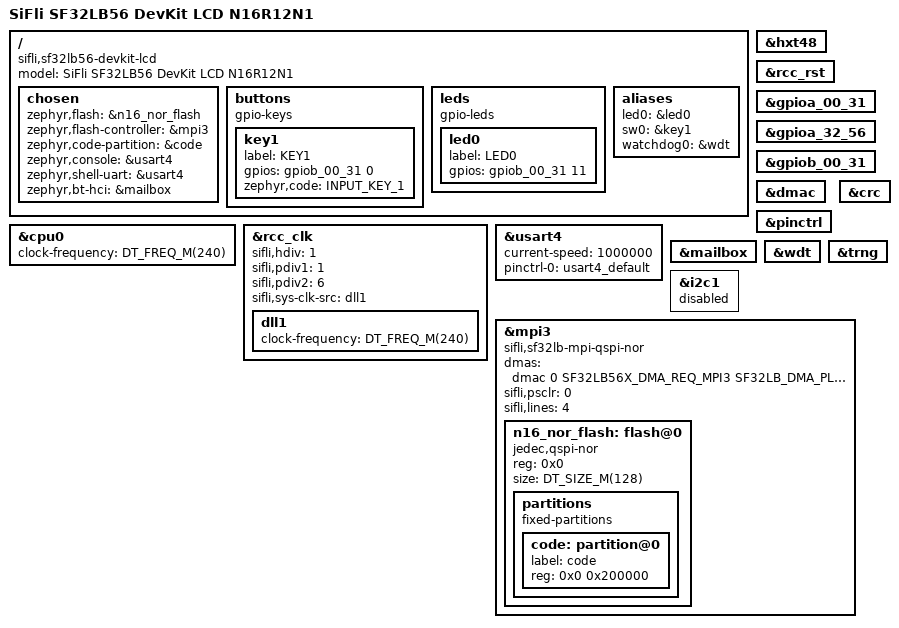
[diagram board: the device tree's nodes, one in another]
/*
 * Copyright (c) 2026 Hraph
 * SPDX-License-Identifier: Apache-2.0
 *
 * SF32LB56-LCD DevKit with N16R12N1 module
 */

/dts-v1/;

#include <sifli/sf32lb56x.dtsi>
#include <sifli/sf32lb56x-ram.dtsi>
#include <zephyr/dt-bindings/dma/sf32lb56x-dma.h>
#include <zephyr/dt-bindings/gpio/gpio.h>
#include <zephyr/dt-bindings/input/input-event-codes.h>

#include "sf32lb56_devkit_lcd-pinctrl.dtsi"

/ {
	model = "SiFli SF32LB56 DevKit LCD N16R12N1";
	compatible = "sifli,sf32lb56-devkit-lcd";

	chosen {
		zephyr,flash = &n16_nor_flash;
		zephyr,flash-controller = &mpi3;
		zephyr,code-partition = &code;
		zephyr,console = &usart4;
		zephyr,shell-uart = &usart4;
		zephyr,bt-hci = &mailbox;
	};

	buttons {
		compatible = "gpio-keys";

		key1: key1 {
			label = "KEY1";
			/* PB00 = gpiob_00_31 offset 0, active high (KEY1_PIN=128 in SDK) */
			gpios = <&gpiob_00_31 0 GPIO_ACTIVE_HIGH>;
			zephyr,code = <INPUT_KEY_1>;
		};
	};

	leds {
		compatible = "gpio-leds";

		led0: led0 {
			label = "LED0";
			/* PB11, active high — wiki.sifli.com SF32LB56-DevKit-LCD */
			gpios = <&gpiob_00_31 11 GPIO_ACTIVE_HIGH>;
		};
	};

	aliases {
		led0 = &led0;
		sw0 = &key1;
		watchdog0 = &wdt;
	};
};

&cpu0 {
	clock-frequency = <DT_FREQ_M(240)>;
};

&hxt48 {
	status = "okay";
};

&rcc_clk {
	status = "okay";
	sifli,hdiv = <1>;
	sifli,pdiv1 = <1>;
	sifli,pdiv2 = <6>;
	sifli,sys-clk-src = "dll1";

	dll1 {
		status = "okay";
		clock-frequency = <DT_FREQ_M(240)>;
	};
};

&rcc_rst {
	status = "okay";
};

&gpioa_00_31 {
	status = "okay";
};

&gpioa_32_56 {
	status = "okay";
};

&gpiob_00_31 {
	status = "okay";
};

&dmac {
	status = "okay";
};

&pinctrl {
	status = "okay";
};

/* Console UART4 on CH348 USB-serial (PB16/17, configured by bootloader).
 * Clock is 240MHz but driver assumes 48MHz. 48M/200000=240 → 240M/240=1Mbaud */
&usart4 {
	status = "okay";
	current-speed = <1000000>;  /* bootloader config preserved */
	pinctrl-0 = <&usart4_default>;
	pinctrl-names = "default";
};

&mailbox {
	status = "okay";
};

&wdt {
	status = "okay";
};

&i2c1 {
	status = "disabled";
};

&crc {
	status = "okay";
};

&trng {
	status = "okay";
};

/* N16R12N1 module: 16 MB NOR flash on MPI3 (QSPI3 @ 0x14000000) */
&mpi3 {
	compatible = "sifli,sf32lb-mpi-qspi-nor";
	dmas = <&dmac 0 SF32LB56X_DMA_REQ_MPI3 SF32LB_DMA_PL_MEDIUM>;
	sifli,psclr = <0>;
	sifli,lines = <4>;
	status = "okay";

	n16_nor_flash: flash@0 {
		compatible = "jedec,qspi-nor";
		reg = <0x0>;
		size = <DT_SIZE_M(128)>;  /* 16 MB = 128 Mbit */

		partitions {
			compatible = "fixed-partitions";
			#address-cells = <1>;
			#size-cells = <1>;

			/* HCPU code slot — 2 MB, matches bootloader ptab allocation.
			 * Application overlays may add further partitions. */
			code: partition@0 {
				label = "code";
				reg = <0x0 0x200000>;
			};
		};
	};
};
